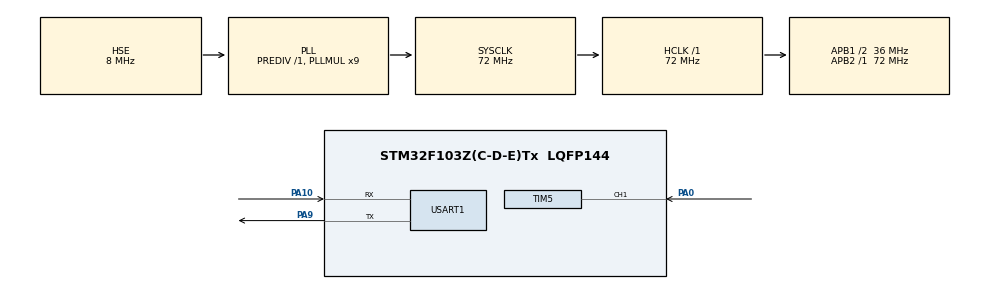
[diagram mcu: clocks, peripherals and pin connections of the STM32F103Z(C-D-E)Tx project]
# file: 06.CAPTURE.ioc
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Mcu.Family=STM32F1
RCC.PLLSourceVirtual=RCC_PLLSOURCE_HSE
PA10.Mode=Asynchronous
RCC.APB1CLKDivider=RCC_HCLK_DIV2
RCC.SYSCLKSource=RCC_SYSCLKSOURCE_PLLCLK
ProjectManager.StackSize=0x400
PA0-WKUP.Signal=S_TIM5_CH1
PA13.Signal=SYS_JTMS-SWDIO
PA9.Mode=Asynchronous
ProjectManager.TargetToolchain=STM32CubeIDE
NVIC.TIM5_IRQn=true\:0\:0\:false\:false\:true\:true\:true
RCC.HCLKFreq_Value=72000000
RCC.APB2TimFreq_Value=72000000
PA9.Signal=USART1_TX
OSC_IN.Signal=RCC_OSC_IN
RCC.USBFreq_Value=72000000
OSC_OUT.Mode=HSE-External-Oscillator
OSC_OUT.Signal=RCC_OSC_OUT
RCC.AHBFreq_Value=72000000
board=custom
RCC.PLLMUL=RCC_PLL_MUL9
RCC.APB2Freq_Value=72000000
PA14.Mode=Serial_Wire
PA13.Mode=Serial_Wire
TIM5.Channel-Input_Capture1_from_TI1=TIM_CHANNEL_1
Mcu.Name=STM32F103Z(C-D-E)Tx
RCC.SYSCLKFreq_VALUE=72000000
Mcu.Package=LQFP144
TIM5.Prescaler=71
OSC_IN.Mode=HSE-External-Oscillator
USART1.VirtualMode=VM_ASYNC
PA10.Signal=USART1_RX
PA14.Signal=SYS_JTCK-SWCLK
ProjectManager.HeapSize=0x200
NVIC.PriorityGroup=NVIC_PRIORITYGROUP_4
RCC.APB1TimFreq_Value=72000000
TIM5.ICFilter_CH1=8
PA0-WKUP.GPIO_PuPd=GPIO_PULLDOWN
SH.S_TIM5_CH1.0=TIM5_CH1,Input_Capture1_from_TI1
NVIC.USART1_IRQn=true\:0\:0\:false\:false\:true\:true\:true
RCC.APB1Freq_Value=36000000

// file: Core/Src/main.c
/* USER CODE BEGIN Header */
/**
 ******************************************************************************
 * @file           : main.c
 * @brief          : Main program body
 ******************************************************************************
 * @attention
 *
 * <h2><center>&copy; Copyright (c) 2021 STMicroelectronics.
 * All rights reserved.</center></h2>
 *
 * This software component is licensed by ST under BSD 3-Clause license,
 * the "License"; You may not use this file except in compliance with the
 * License. You may obtain a copy of the License at:
 *                        opensource.org/licenses/BSD-3-Clause
 *
 ******************************************************************************
 */
/* USER CODE END Header */
#include "main.h"
#include "tim.h"
#include "usart.h"
#include "gpio.h"

void SystemClock_Config(void);

/* USER CODE BEGIN 0 */
uint32_t capture_Buf[3] = { 0 }; //存放计数值
uint8_t capture_Cnt = 0;  //状态标志位
uint32_t high_time;  //高电平时间
/* USER CODE END 0 */

int main(void)
{

  /* MCU Configuration--------------------------------------------------------*/

  /* Reset of all peripherals, Initializes the Flash interface and the Systick. */
  HAL_Init();

  /* Configure the system clock */
  SystemClock_Config();

  /* Initialize all configured peripherals */
  MX_GPIO_Init();
  MX_TIM5_Init();
  MX_USART1_UART_Init();

  /* Infinite loop */
	while (1) {

    /* USER CODE BEGIN 3 */
		switch (capture_Cnt) {
		case 0:
			capture_Cnt++;
			__HAL_TIM_SET_CAPTUREPOLARITY(&htim5, TIM_CHANNEL_1, TIM_INPUTCHANNELPOLARITY_RISING);
			HAL_TIM_IC_Start_IT(&htim5, TIM_CHANNEL_1);
			break;
		case 3:
			high_time = capture_Buf[1] - capture_Buf[0];
			HAL_UART_Transmit(&huart1, (uint8_t*)high_time, 1, 0xffff);
			HAL_Delay(1000);
			capture_Cnt = 0;
			break;
		}
	}
  /* USER CODE END 3 */
}

void SystemClock_Config(void)
{
  RCC_OscInitTypeDef RCC_OscInitStruct = {0};
  RCC_ClkInitTypeDef RCC_ClkInitStruct = {0};

  /** Initializes the RCC Oscillators according to the specified parameters
  * in the RCC_OscInitTypeDef structure.
  */
  RCC_OscInitStruct.OscillatorType = RCC_OSCILLATORTYPE_HSE;
  RCC_OscInitStruct.HSEState = RCC_HSE_ON;
  RCC_OscInitStruct.HSEPredivValue = RCC_HSE_PREDIV_DIV1;
  RCC_OscInitStruct.HSIState = RCC_HSI_ON;
  RCC_OscInitStruct.PLL.PLLState = RCC_PLL_ON;
  RCC_OscInitStruct.PLL.PLLSource = RCC_PLLSOURCE_HSE;
  RCC_OscInitStruct.PLL.PLLMUL = RCC_PLL_MUL9;
  if (HAL_RCC_OscConfig(&RCC_OscInitStruct) != HAL_OK)
  {
    Error_Handler();
  }
  /** Initializes the CPU, AHB and APB buses clocks
  */
  RCC_ClkInitStruct.ClockType = RCC_CLOCKTYPE_HCLK|RCC_CLOCKTYPE_SYSCLK
                              |RCC_CLOCKTYPE_PCLK1|RCC_CLOCKTYPE_PCLK2;
  RCC_ClkInitStruct.SYSCLKSource = RCC_SYSCLKSOURCE_PLLCLK;
  RCC_ClkInitStruct.AHBCLKDivider = RCC_SYSCLK_DIV1;
  RCC_ClkInitStruct.APB1CLKDivider = RCC_HCLK_DIV2;
  RCC_ClkInitStruct.APB2CLKDivider = RCC_HCLK_DIV1;

  if (HAL_RCC_ClockConfig(&RCC_ClkInitStruct, FLASH_LATENCY_2) != HAL_OK)
  {
    Error_Handler();
  }
}

/* USER CODE BEGIN 4 */
void HAL_TIM_IC_CaptureCallback(TIM_HandleTypeDef *htim)
{
	if(TIM5 == htim->Instance){
		switch(capture_Cnt){
		case 1:
			capture_Buf[0] = HAL_TIM_ReadCapturedValue(&htim5, TIM_CHANNEL_1);
			TIM_RESET_CAPTUREPOLARITY(&htim5, TIM_CHANNEL_1);
			TIM_SET_CAPTUREPOLARITY(&htim5, TIM_CHANNEL_1, TIM_ICPOLARITY_FALLING);
			capture_Cnt++;
			break;
		case 2:
			capture_Buf[1] = HAL_TIM_ReadCapturedValue(&htim5, TIM_CHANNEL_1);
			HAL_TIM_IC_Stop_IT(&htim5, TIM_CHANNEL_1);
			capture_Cnt++;
		}
	}
}
/* USER CODE END 4 */

void Error_Handler(void)
{
	__disable_irq();
	while (1) {
	}
}

/************************ (C) COPYRIGHT STMicroelectronics *****END OF FILE****/
